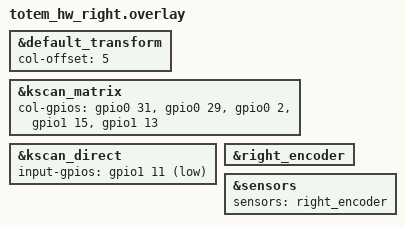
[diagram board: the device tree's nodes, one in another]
#include "totem_hw.dtsi"

&default_transform {
    col-offset = <5>;
};

&kscan_matrix {
    col-gpios
        = <&gpio0 31 GPIO_ACTIVE_HIGH>
        , <&gpio0 29 GPIO_ACTIVE_HIGH>
        , <&gpio0 2  GPIO_ACTIVE_HIGH>
        , <&gpio1 15 GPIO_ACTIVE_HIGH>
        , <&gpio1 13 GPIO_ACTIVE_HIGH>
        ;
};

&kscan_direct {
    input-gpios = <&gpio1 11 (GPIO_ACTIVE_LOW | GPIO_PULL_UP)>;
};

&right_encoder {
    status = "okay";
};

&sensors {
    sensors = <&right_encoder>;
};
